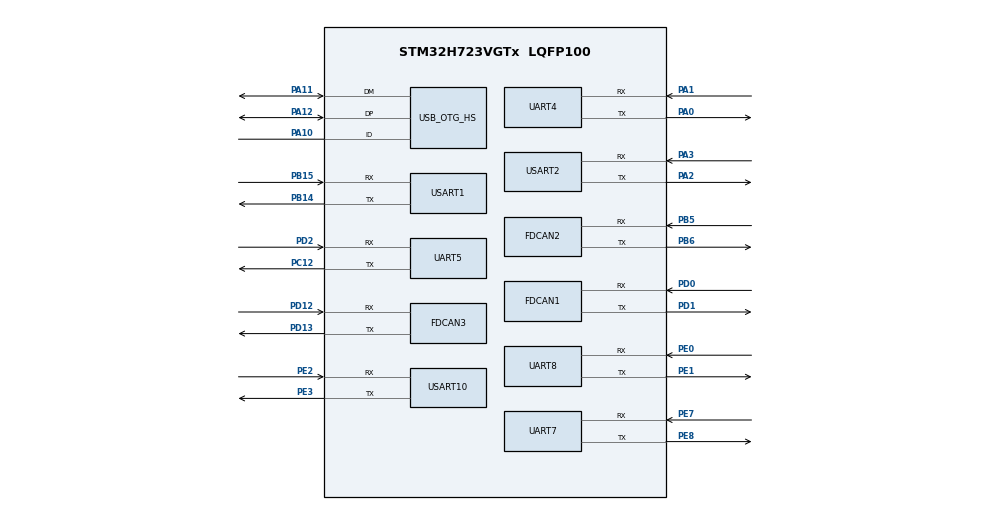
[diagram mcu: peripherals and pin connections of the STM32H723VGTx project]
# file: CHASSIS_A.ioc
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CORTEX_M7.default_mode_Activation=1
FDCAN1.AutoRetransmission=ENABLE
FDCAN1.CalculateBaudRateNominal=1000000
FDCAN1.CalculateTimeBitNominal=1000
FDCAN1.CalculateTimeQuantumNominal=62.5
FDCAN1.DataPrescaler=5
FDCAN1.DataSyncJumpWidth=2
FDCAN1.DataTimeSeg1=13
FDCAN1.DataTimeSeg2=2
FDCAN1.ExtFiltersNbr=1
FDCAN1.MessageRAMOffset=0
FDCAN1.NominalPrescaler=5
FDCAN1.NominalSyncJumpWidth=2
FDCAN1.NominalTimeSeg1=13
FDCAN1.NominalTimeSeg2=2
FDCAN1.RxFifo0ElmtsNbr=32
FDCAN1.StdFiltersNbr=1
FDCAN1.TxFifoQueueElmtsNbr=16
FDCAN2.AutoRetransmission=ENABLE
FDCAN2.CalculateBaudRateNominal=1000000
FDCAN2.CalculateTimeBitNominal=1000
FDCAN2.CalculateTimeQuantumNominal=62.5
FDCAN2.DataPrescaler=5
FDCAN2.DataSyncJumpWidth=2
FDCAN2.DataTimeSeg1=13
FDCAN2.DataTimeSeg2=2
FDCAN2.ExtFiltersNbr=1
FDCAN2.MessageRAMOffset=256
FDCAN2.NominalPrescaler=5
FDCAN2.NominalSyncJumpWidth=2
FDCAN2.NominalTimeSeg1=13
FDCAN2.NominalTimeSeg2=2
FDCAN2.RxFifo0ElmtsNbr=32
FDCAN2.StdFiltersNbr=1
FDCAN2.TxFifoQueueElmtsNbr=16
FDCAN3.AutoRetransmission=ENABLE
FDCAN3.CalculateBaudRateNominal=1000000
FDCAN3.CalculateTimeBitNominal=1000
FDCAN3.CalculateTimeQuantumNominal=62.5
FDCAN3.DataPrescaler=5
FDCAN3.DataSyncJumpWidth=2
FDCAN3.DataTimeSeg1=13
FDCAN3.DataTimeSeg2=2
FDCAN3.ExtFiltersNbr=1
FDCAN3.MessageRAMOffset=512
FDCAN3.NominalPrescaler=5
FDCAN3.NominalSyncJumpWidth=2
FDCAN3.NominalTimeSeg1=13
FDCAN3.NominalTimeSeg2=2
FDCAN3.RxFifo0ElmtsNbr=32
FDCAN3.StdFiltersNbr=1
FDCAN3.TxFifoQueueElmtsNbr=16
FREERTOS.Tasks01=defaultTask,32,512,StartDefaultTask,Default,NULL,Dynamic,NULL,NULL
FREERTOS.configCHECK_FOR_STACK_OVERFLOW=2
FREERTOS.configENABLE_FPU=1
FREERTOS.configMAX_TASK_NAME_LEN=24
FREERTOS.configQUEUE_REGISTRY_SIZE=16
FREERTOS.configTOTAL_HEAP_SIZE=65536
FREERTOS.configUSE_MALLOC_FAILED_HOOK=1
Mcu.Family=STM32H7
Mcu.Name=STM32H723VGTx
Mcu.Package=LQFP100
NVIC.FDCAN1_IT0_IRQn=true\:5\:0\:false\:false\:true\:true\:true\:true\:true
NVIC.FDCAN2_IT0_IRQn=true\:5\:0\:false\:false\:true\:true\:true\:true\:true
NVIC.FDCAN3_IT0_IRQn=true\:5\:0\:false\:false\:true\:true\:true\:true\:true
NVIC.PriorityGroup=NVIC_PRIORITYGROUP_4
NVIC.TIM1_UP_IRQn=true\:15\:0\:false\:false\:true\:false\:false\:true\:true
NVIC.TimeBase=TIM1_UP_IRQn
NVIC.TimeBaseIP=TIM1
PA0.Mode=Asynchronous
PA0.Signal=UART4_TX
PA1.Mode=Asynchronous
PA1.Signal=UART4_RX
PA10.Mode=OTG/Dual_Role_Device_FS
PA10.Signal=USB_OTG_HS_ID
PA11.Mode=OTG/Dual_Role_Device_FS
PA11.Signal=USB_OTG_HS_DM
PA12.Mode=OTG/Dual_Role_Device_FS
PA12.Signal=USB_OTG_HS_DP
PA13(JTMS/SWDIO).Mode=Serial_Wire
PA13(JTMS/SWDIO).Signal=DEBUG_JTMS-SWDIO
PA14(JTCK/SWCLK).Mode=Serial_Wire
PA14(JTCK/SWCLK).Signal=DEBUG_JTCK-SWCLK
PA2.Mode=Asynchronous
PA2.Signal=USART2_TX
PA3.Mode=Asynchronous
PA3.Signal=USART2_RX
PB14.Mode=Asynchronous
PB14.Signal=USART1_TX
PB15.Mode=Asynchronous
PB15.Signal=USART1_RX
PB5.Mode=FDCAN_Activate
PB5.Signal=FDCAN2_RX
PB6.Mode=FDCAN_Activate
PB6.Signal=FDCAN2_TX
PC12.GPIO_Speed=GPIO_SPEED_FREQ_HIGH
PC12.Mode=Asynchronous
PC12.Signal=UART5_TX
PD0.Mode=FDCAN_Activate
PD0.Signal=FDCAN1_RX
PD1.Mode=FDCAN_Activate
PD1.Signal=FDCAN1_TX
PD12.Mode=FDCAN_Activate
PD12.Signal=FDCAN3_RX
PD13.Mode=FDCAN_Activate
PD13.Signal=FDCAN3_TX
PD2.Mode=Asynchronous
PD2.Signal=UART5_RX
PE0.Mode=Asynchronous
PE0.Signal=UART8_RX
PE1.Mode=Asynchronous
PE1.Signal=UART8_TX
PE2.Mode=Asynchronous
PE2.Signal=USART10_RX
PE3.Mode=Asynchronous
PE3.Signal=USART10_TX
PE7.Mode=Asynchronous
PE7.Signal=UART7_RX
PE8.Mode=Asynchronous
PE8.Signal=UART7_TX
PH0-OSC_IN.Mode=HSE-External-Oscillator
PH0-OSC_IN.Signal=RCC_OSC_IN
PH1-OSC_OUT.Mode=HSE-External-Oscillator
PH1-OSC_OUT.Signal=RCC_OSC_OUT
ProjectManager.HeapSize=0x200
ProjectManager.StackSize=0x400
ProjectManager.TargetToolchain=MDK-ARM V5.32
RCC.ADCFreq_Value=200000000
RCC.APB1Freq_Value=137500000
RCC.APB2Freq_Value=137500000
RCC.APB3Freq_Value=137500000
RCC.APB4Freq_Value=137500000
RCC.CortexFreq_Value=550000000
RCC.D1PPRE=RCC_APB3_DIV2
RCC.D2PPRE1=RCC_APB1_DIV2
RCC.D2PPRE2=RCC_APB2_DIV2
RCC.D3PPRE=RCC_APB4_DIV2
RCC.DIVM1=2
RCC.DIVM2=5
RCC.DIVM3=5
RCC.DIVN1=44
RCC.DIVN2=80
RCC.DIVN3=40
RCC.DIVP1=1
RCC.DIVQ1=4
RCC.DIVQ2=5
RCC.FDCANCLockSelection=RCC_FDCANCLKSOURCE_PLL2
RCC.HCLKFreq_Value=275000000
RCC.HPRE=RCC_HCLK_DIV2
RCC.PLLFRACN=0
RCC.PLLSourceVirtual=RCC_PLLSOURCE_HSE
RCC.SYSCLKFreq_VALUE=550000000
RCC.SYSCLKSource=RCC_SYSCLKSOURCE_PLLCLK
RCC.USBCLockSelection=RCC_USBCLKSOURCE_PLL3
RCC.USBFreq_Value=100000000
USART1.VirtualMode-Asynchronous=VM_ASYNC
USART10.VirtualMode=VM_ASYNC
USART2.VirtualMode-Asynchronous=VM_ASYNC
USB_OTG_HS.VirtualMode-OTG/Dual_Role_Device_FS=Device_Role_Device_FS
VP_FREERTOS_VS_CMSIS_V2.Mode=CMSIS_V2
VP_MEMORYMAP_VS_MEMORYMAP.Mode=CurAppReg
VP_SYS_VS_tim1.Mode=TIM1
VP_TIM13_VS_ClockSourceINT.Mode=Enable_Timer
VP_TIM14_VS_ClockSourceINT.Mode=Enable_Timer
VP_TIM6_VS_ClockSourceINT.Mode=Enable_Timer
VP_TIM7_VS_ClockSourceINT.Mode=Enable_Timer
VP_USB_OTG_HS1_USB_OTG_HS_DR.Mode=activate
board=custom

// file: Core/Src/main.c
/* USER CODE BEGIN Header */
/**
  ******************************************************************************
  * @file           : main.c
  * @brief          : Main program body
  ******************************************************************************
  * @attention
  *
  * Copyright (c) 2026 STMicroelectronics.
  * All rights reserved.
  *
  * This software is licensed under terms that can be found in the LICENSE file
  * in the root directory of this software component.
  * If no LICENSE file comes with this software, it is provided AS-IS.
  *
  ******************************************************************************
  */
/* USER CODE END Header */
#include "main.h"
#include "FreeRTOS.h"
#include "cmsis_os2.h"
#include "fdcan.h"
#include "tim.h"
#include "usart.h"
#include "usb_otg.h"
#include "gpio.h"

/* USER CODE BEGIN Includes */
#include "Bsp_Control_Timer.h"

/* USER CODE END Includes */

void SystemClock_Config(void);
void PeriphCommonClock_Config(void);
static void MPU_Config(void);
void MX_FREERTOS_Init(void);

int main(void)
{

  /* MPU Configuration--------------------------------------------------------*/
  MPU_Config();

  /* MCU Configuration--------------------------------------------------------*/

  /* Reset of all peripherals, Initializes the Flash interface and the Systick. */
  HAL_Init();

  /* Configure the system clock */
  SystemClock_Config();

  /* Configure the peripherals common clocks */
  PeriphCommonClock_Config();

  /* Initialize all configured peripherals */
  MX_GPIO_Init();
  MX_FDCAN1_Init();
  MX_FDCAN2_Init();
  MX_FDCAN3_Init();
  MX_TIM6_Init();
  MX_TIM7_Init();
  MX_TIM13_Init();
  MX_TIM14_Init();
  MX_UART4_Init();
  MX_UART7_Init();
  MX_UART8_Init();
  MX_USART1_UART_Init();
  MX_USART10_UART_Init();
  MX_USB_OTG_HS_PCD_Init();
  MX_UART5_Init();
  MX_USART2_UART_Init();

  /* Init scheduler */
  osKernelInitialize();  /* Call init function for freertos objects (in cmsis_os2.c) */
  MX_FREERTOS_Init();

  /* Start scheduler */
  osKernelStart();

  /* We should never get here as control is now taken by the scheduler */

  /* Infinite loop */
  while (1)
  {

  }
}

void SystemClock_Config(void)
{
  RCC_OscInitTypeDef RCC_OscInitStruct = {0};
  RCC_ClkInitTypeDef RCC_ClkInitStruct = {0};

  /** Supply configuration update enable
  */
  HAL_PWREx_ConfigSupply(PWR_LDO_SUPPLY);

  /** Configure the main internal regulator output voltage
  */
  __HAL_PWR_VOLTAGESCALING_CONFIG(PWR_REGULATOR_VOLTAGE_SCALE0);

  while(!__HAL_PWR_GET_FLAG(PWR_FLAG_VOSRDY)) {}

  /** Initializes the RCC Oscillators according to the specified parameters
  * in the RCC_OscInitTypeDef structure.
  */
  RCC_OscInitStruct.OscillatorType = RCC_OSCILLATORTYPE_HSE;
  RCC_OscInitStruct.HSEState = RCC_HSE_ON;
  RCC_OscInitStruct.PLL.PLLState = RCC_PLL_ON;
  RCC_OscInitStruct.PLL.PLLSource = RCC_PLLSOURCE_HSE;
  RCC_OscInitStruct.PLL.PLLM = 2;
  RCC_OscInitStruct.PLL.PLLN = 44;
  RCC_OscInitStruct.PLL.PLLP = 1;
  RCC_OscInitStruct.PLL.PLLQ = 4;
  RCC_OscInitStruct.PLL.PLLR = 2;
  RCC_OscInitStruct.PLL.PLLRGE = RCC_PLL1VCIRANGE_3;
  RCC_OscInitStruct.PLL.PLLVCOSEL = RCC_PLL1VCOWIDE;
  RCC_OscInitStruct.PLL.PLLFRACN = 0;
  if (HAL_RCC_OscConfig(&RCC_OscInitStruct) != HAL_OK)
  {
    Error_Handler();
  }

  /** Initializes the CPU, AHB and APB buses clocks
  */
  RCC_ClkInitStruct.ClockType = RCC_CLOCKTYPE_HCLK|RCC_CLOCKTYPE_SYSCLK
                              |RCC_CLOCKTYPE_PCLK1|RCC_CLOCKTYPE_PCLK2
                              |RCC_CLOCKTYPE_D3PCLK1|RCC_CLOCKTYPE_D1PCLK1;
  RCC_ClkInitStruct.SYSCLKSource = RCC_SYSCLKSOURCE_PLLCLK;
  RCC_ClkInitStruct.SYSCLKDivider = RCC_SYSCLK_DIV1;
  RCC_ClkInitStruct.AHBCLKDivider = RCC_HCLK_DIV2;
  RCC_ClkInitStruct.APB3CLKDivider = RCC_APB3_DIV2;
  RCC_ClkInitStruct.APB1CLKDivider = RCC_APB1_DIV2;
  RCC_ClkInitStruct.APB2CLKDivider = RCC_APB2_DIV2;
  RCC_ClkInitStruct.APB4CLKDivider = RCC_APB4_DIV2;

  if (HAL_RCC_ClockConfig(&RCC_ClkInitStruct, FLASH_LATENCY_3) != HAL_OK)
  {
    Error_Handler();
  }
}

void PeriphCommonClock_Config(void)
{
  RCC_PeriphCLKInitTypeDef PeriphClkInitStruct = {0};

  /** Initializes the peripherals clock
  */
  PeriphClkInitStruct.PeriphClockSelection = RCC_PERIPHCLK_FDCAN;
  PeriphClkInitStruct.PLL2.PLL2M = 5;
  PeriphClkInitStruct.PLL2.PLL2N = 80;
  PeriphClkInitStruct.PLL2.PLL2P = 2;
  PeriphClkInitStruct.PLL2.PLL2Q = 5;
  PeriphClkInitStruct.PLL2.PLL2R = 2;
  PeriphClkInitStruct.PLL2.PLL2RGE = RCC_PLL2VCIRANGE_2;
  PeriphClkInitStruct.PLL2.PLL2VCOSEL = RCC_PLL2VCOWIDE;
  PeriphClkInitStruct.PLL2.PLL2FRACN = 0;
  PeriphClkInitStruct.FdcanClockSelection = RCC_FDCANCLKSOURCE_PLL2;
  if (HAL_RCCEx_PeriphCLKConfig(&PeriphClkInitStruct) != HAL_OK)
  {
    Error_Handler();
  }
}

 /* MPU Configuration */

void MPU_Config(void)
{
  MPU_Region_InitTypeDef MPU_InitStruct = {0};

  /* Disables the MPU */
  HAL_MPU_Disable();

  /** Initializes and configures the Region and the memory to be protected
  */
  MPU_InitStruct.Enable = MPU_REGION_ENABLE;
  MPU_InitStruct.Number = MPU_REGION_NUMBER0;
  MPU_InitStruct.BaseAddress = 0x0;
  MPU_InitStruct.Size = MPU_REGION_SIZE_4GB;
  MPU_InitStruct.SubRegionDisable = 0x87;
  MPU_InitStruct.TypeExtField = MPU_TEX_LEVEL0;
  MPU_InitStruct.AccessPermission = MPU_REGION_NO_ACCESS;
  MPU_InitStruct.DisableExec = MPU_INSTRUCTION_ACCESS_DISABLE;
  MPU_InitStruct.IsShareable = MPU_ACCESS_SHAREABLE;
  MPU_InitStruct.IsCacheable = MPU_ACCESS_NOT_CACHEABLE;
  MPU_InitStruct.IsBufferable = MPU_ACCESS_NOT_BUFFERABLE;

  HAL_MPU_ConfigRegion(&MPU_InitStruct);
  /* Enables the MPU */
  HAL_MPU_Enable(MPU_PRIVILEGED_DEFAULT);

}

void HAL_TIM_PeriodElapsedCallback(TIM_HandleTypeDef *htim)
{
  if (htim->Instance == TIM1)
  {
    HAL_IncTick();
  }
  /* USER CODE BEGIN Callback 1 */
  BspTim_DispatchPeriodElapsedFromISR(htim);

  /* USER CODE END Callback 1 */
}

void Error_Handler(void)
{
  __disable_irq();
  while (1)
  {
  }
}

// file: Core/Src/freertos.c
/* USER CODE BEGIN Header */
/**
  ******************************************************************************
  * File Name          : freertos.c
  * Description        : Code for freertos applications
  ******************************************************************************
  * @attention
  *
  * Copyright (c) 2026 STMicroelectronics.
  * All rights reserved.
  *
  * This software is licensed under terms that can be found in the LICENSE file
  * in the root directory of this software component.
  * If no LICENSE file comes with this software, it is provided AS-IS.
  *
  ******************************************************************************
  */
/* USER CODE END Header */

#include "FreeRTOS.h"
#include "task.h"
#include "main.h"
#include "FreeRTOS.h"
#include "cmsis_os2.h"

/* USER CODE BEGIN Includes */
#include "app_rtos.h"

/* USER CODE END Includes */

/* Definitions for defaultTask */
osThreadId_t defaultTaskHandle;
const osThreadAttr_t defaultTask_attributes = {
  .name = "defaultTask",
  .stack_size = 512 * 4,
  .priority = (osPriority_t) osPriorityAboveNormal,
};

void StartDefaultTask(void *argument);

void MX_FREERTOS_Init(void); /* (MISRA C 2004 rule 8.1) */

/* Hook prototypes */
void vApplicationStackOverflowHook(xTaskHandle xTask, char *pcTaskName);
void vApplicationMallocFailedHook(void);

/* USER CODE BEGIN 4 */
void vApplicationStackOverflowHook(xTaskHandle xTask, char *pcTaskName)
{
  (void)xTask;
  appRtosFaultFile = pcTaskName;
  AppRtos_Panic(APP_RTOS_FAULT_STACK_OVERFLOW);
}
/* USER CODE END 4 */

/* USER CODE BEGIN 5 */
void vApplicationMallocFailedHook(void)
{
  AppRtos_Panic(APP_RTOS_FAULT_MALLOC_FAILED);
}
/* USER CODE END 5 */

void MX_FREERTOS_Init(void) {
  /* USER CODE BEGIN Init */
  if (!AppRtos_Init())
  {
    AppRtos_Panic(APP_RTOS_FAULT_OBJECT_CREATE);
  }

  /* USER CODE END Init */

  /* Create the thread(s) */
  /* creation of defaultTask */
  defaultTaskHandle = osThreadNew(StartDefaultTask, NULL, &defaultTask_attributes);

}

void StartDefaultTask(void *argument)
{
  /* USER CODE BEGIN StartDefaultTask */
  (void)argument;
  AppRtos_Bootstrap();
  osThreadExit();
  /* USER CODE END StartDefaultTask */
}

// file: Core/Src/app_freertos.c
#include "app_freertos.h"

#include <string.h>

#include "FreeRTOS.h"
#include "fdcan.h"
#include "task.h"

#define APP_CAN_RX_QUEUE_LENGTH           64U
#define APP_COMMAND_QUEUE_LENGTH           4U
#define APP_COMM_QUEUE_LENGTH             16U
#define APP_TELEMETRY_QUEUE_LENGTH         4U

#define APP_CONTROL_PERIOD_MS              1U
#define APP_NAVIGATION_PERIOD_MS          10U
#define APP_SAFETY_PERIOD_MS              10U
#define APP_MONITOR_PERIOD_MS            100U

#define APP_CAN_RX_TASK_STACK_SIZE       1536U
#define APP_CONTROL_TASK_STACK_SIZE      2048U
#define APP_NAVIGATION_TASK_STACK_SIZE   3072U
#define APP_COMM_TASK_STACK_SIZE         2048U
#define APP_SAFETY_TASK_STACK_SIZE       1024U
#define APP_MONITOR_TASK_STACK_SIZE      1024U

osThreadId_t appCanRxTaskHandle;
osThreadId_t appControlTaskHandle;
osThreadId_t appNavigationTaskHandle;
osThreadId_t appCommunicationTaskHandle;
osThreadId_t appSafetyTaskHandle;
osThreadId_t appMonitorTaskHandle;

osMessageQueueId_t appCanRxQueueHandle;
osMessageQueueId_t appChassisCommandQueueHandle;
osMessageQueueId_t appMechanismCommandQueueHandle;
osMessageQueueId_t appTrajectoryQueueHandle;
osMessageQueueId_t appCommunicationQueueHandle;
osMessageQueueId_t appTelemetryQueueHandle;
osEventFlagsId_t appSystemEventHandle;
osMutexId_t appRobotStateMutexHandle;

volatile app_freertos_fault_t appFreertosFaultCode = APP_FREERTOS_FAULT_NONE;
volatile uint32_t appFreertosFaultLine;
const char * volatile appFreertosFaultFile;

static app_robot_state_t app_robot_state;
static app_runtime_stats_t app_runtime_stats;
static volatile uint32_t app_can_error_mask;

static void AppCanRxTask(void *argument);
static void AppControlTask(void *argument);
static void AppNavigationTask(void *argument);
static void AppCommunicationTask(void *argument);
static void AppSafetyTask(void *argument);
static void AppMonitorTask(void *argument);

static const osThreadAttr_t app_can_rx_task_attributes =
{
    .name = "canRxTask",
    .stack_size = APP_CAN_RX_TASK_STACK_SIZE,
    .priority = osPriorityHigh
};

static const osThreadAttr_t app_control_task_attributes =
{
    .name = "controlTask",
    .stack_size = APP_CONTROL_TASK_STACK_SIZE,
    .priority = osPriorityRealtime
};

static const osThreadAttr_t app_navigation_task_attributes =
{
    .name = "navigationTask",
    .stack_size = APP_NAVIGATION_TASK_STACK_SIZE,
    .priority = osPriorityAboveNormal
};

static const osThreadAttr_t app_communication_task_attributes =
{
    .name = "communicationTask",
    .stack_size = APP_COMM_TASK_STACK_SIZE,
    .priority = osPriorityNormal
};

static const osThreadAttr_t app_safety_task_attributes =
{
    .name = "safetyTask",
    .stack_size = APP_SAFETY_TASK_STACK_SIZE,
    .priority = osPriorityHigh
};

static const osThreadAttr_t app_monitor_task_attributes =
{
    .name = "monitorTask",
    .stack_size = APP_MONITOR_TASK_STACK_SIZE,
    .priority = osPriorityLow
};

static const osMessageQueueAttr_t app_can_rx_queue_attributes =
{
    .name = "canRxQueue"
};

static const osMessageQueueAttr_t app_chassis_command_queue_attributes =
{
    .name = "chassisCmdQueue"
};

static const osMessageQueueAttr_t app_mechanism_command_queue_attributes =
{
    .name = "mechanismCmdQueue"
};

static const osMessageQueueAttr_t app_trajectory_queue_attributes =
{
    .name = "trajectoryQueue"
};

static const osMessageQueueAttr_t app_communication_queue_attributes =
{
    .name = "communicationQueue"
};

static const osMessageQueueAttr_t app_telemetry_queue_attributes =
{
    .name = "telemetryQueue"
};

static const osEventFlagsAttr_t app_system_event_attributes =
{
    .name = "systemEvents"
};

static const osMutexAttr_t app_state_mutex_attributes =
{
    .name = "robotStateMutex",
    .attr_bits = osMutexPrioInherit
};

static uint32_t App_MsToTicks(uint32_t milliseconds)
{
    uint64_t ticks;

    ticks = ((uint64_t)milliseconds * osKernelGetTickFreq() + 999U) / 1000U;
    if ((milliseconds > 0U) && (ticks == 0U))
    {
        ticks = 1U;
    }
    return (uint32_t)ticks;
}

static bool App_WaitForInitialization(void)
{
    uint32_t flags;

    flags = osEventFlagsWait(appSystemEventHandle,
                             APP_EVENT_INIT_DONE | APP_EVENT_INIT_FAILED,
                             osFlagsWaitAny | osFlagsNoClear, osWaitForever);
    return ((flags & osFlagsError) == 0U)
        && ((flags & APP_EVENT_INIT_DONE) != 0U);
}

static bool App_StartCan(FDCAN_HandleTypeDef *handle, uint32_t ready_event)
{
    FDCAN_FilterTypeDef filter = {0};

    filter.IdType = FDCAN_STANDARD_ID;
    filter.FilterIndex = 0U;
    filter.FilterType = FDCAN_FILTER_MASK;
    filter.FilterConfig = FDCAN_FILTER_TO_RXFIFO0;
    filter.FilterID1 = 0U;
    filter.FilterID2 = 0U;
    if (HAL_FDCAN_ConfigFilter(handle, &filter) != HAL_OK)
    {
        return false;
    }

    filter.IdType = FDCAN_EXTENDED_ID;
    if (HAL_FDCAN_ConfigFilter(handle, &filter) != HAL_OK)
    {
        return false;
    }

    if (HAL_FDCAN_ConfigGlobalFilter(handle, FDCAN_REJECT,
                                     FDCAN_REJECT, FDCAN_REJECT_REMOTE,
                                     FDCAN_REJECT_REMOTE) != HAL_OK)
    {
        return false;
    }

    if (HAL_FDCAN_Start(handle) != HAL_OK)
    {
        return false;
    }

    if (HAL_FDCAN_ActivateNotification(
            handle, FDCAN_IT_RX_FIFO0_NEW_MESSAGE | FDCAN_IT_BUS_OFF,
            0U) != HAL_OK)
    {
        (void)HAL_FDCAN_Stop(handle);
        return false;
    }

    (void)osEventFlagsSet(appSystemEventHandle, ready_event);
    return true;
}

static uint8_t App_FdcanDataLengthToBytes(uint32_t data_length)
{
    switch (data_length)
    {
    case FDCAN_DLC_BYTES_0:
        return 0U;
    case FDCAN_DLC_BYTES_1:
        return 1U;
    case FDCAN_DLC_BYTES_2:
        return 2U;
    case FDCAN_DLC_BYTES_3:
        return 3U;
    case FDCAN_DLC_BYTES_4:
        return 4U;
    case FDCAN_DLC_BYTES_5:
        return 5U;
    case FDCAN_DLC_BYTES_6:
        return 6U;
    case FDCAN_DLC_BYTES_7:
        return 7U;
    case FDCAN_DLC_BYTES_8:
        return 8U;
    default:
        return 0U;
    }
}

static bool App_GetCanBus(const FDCAN_HandleTypeDef *handle,
                          app_can_bus_t *bus)
{
    if (handle == &hfdcan1)
    {
        *bus = APP_CAN_BUS_1;
    }
    else if (handle == &hfdcan2)
    {
        *bus = APP_CAN_BUS_2;
    }
    else if (handle == &hfdcan3)
    {
        *bus = APP_CAN_BUS_3;
    }
    else
    {
        return false;
    }
    return true;
}

static bool App_PutLatestChassisCommand(
    const app_chassis_command_t *command, uint32_t timeout_ticks)
{
    app_chassis_command_t discarded;

    if (osMessageQueuePut(appChassisCommandQueueHandle, command, 0U,
                          timeout_ticks) == osOK)
    {
        return true;
    }
    if (osMessageQueueGet(appChassisCommandQueueHandle, &discarded, NULL,
                          0U) != osOK)
    {
        return false;
    }
    return osMessageQueuePut(appChassisCommandQueueHandle, command, 0U,
                             0U) == osOK;
}

static bool App_PutLatestMechanismCommand(
    const app_mechanism_command_t *command, uint32_t timeout_ticks)
{
    app_mechanism_command_t discarded;

    if (osMessageQueuePut(appMechanismCommandQueueHandle, command, 0U,
                          timeout_ticks) == osOK)
    {
        return true;
    }
    if (osMessageQueueGet(appMechanismCommandQueueHandle, &discarded, NULL,
                          0U) != osOK)
    {
        return false;
    }
    return osMessageQueuePut(appMechanismCommandQueueHandle, command, 0U,
                             0U) == osOK;
}

bool AppFreertos_Init(void)
{
    memset(&app_robot_state, 0, sizeof(app_robot_state));
    memset(&app_runtime_stats, 0, sizeof(app_runtime_stats));
    app_can_error_mask = 0U;

    appCanRxQueueHandle = osMessageQueueNew(APP_CAN_RX_QUEUE_LENGTH,
        sizeof(app_can_frame_t), &app_can_rx_queue_attributes);
    appChassisCommandQueueHandle = osMessageQueueNew(
        APP_COMMAND_QUEUE_LENGTH, sizeof(app_chassis_command_t),
        &app_chassis_command_queue_attributes);
    appMechanismCommandQueueHandle = osMessageQueueNew(
        APP_COMMAND_QUEUE_LENGTH, sizeof(app_mechanism_command_t),
        &app_mechanism_command_queue_attributes);
    appTrajectoryQueueHandle = osMessageQueueNew(
        APP_TRAJECTORY_QUEUE_LENGTH, sizeof(app_trajectory_point_t),
        &app_trajectory_queue_attributes);
    appCommunicationQueueHandle = osMessageQueueNew(
        APP_COMM_QUEUE_LENGTH, sizeof(app_comm_packet_t),
        &app_communication_queue_attributes);
    appTelemetryQueueHandle = osMessageQueueNew(
        APP_TELEMETRY_QUEUE_LENGTH, sizeof(app_runtime_stats_t),
        &app_telemetry_queue_attributes);
    appSystemEventHandle = osEventFlagsNew(&app_system_event_attributes);
    appRobotStateMutexHandle = osMutexNew(&app_state_mutex_attributes);

    if ((appCanRxQueueHandle == NULL)
        || (appChassisCommandQueueHandle == NULL)
        || (appMechanismCommandQueueHandle == NULL)
        || (appTrajectoryQueueHandle == NULL)
        || (appCommunicationQueueHandle == NULL)
        || (appTelemetryQueueHandle == NULL)
        || (appSystemEventHandle == NULL)
        || (appRobotStateMutexHandle == NULL))
    {
        return false;
    }

    appCanRxTaskHandle = osThreadNew(AppCanRxTask, NULL,
                                     &app_can_rx_task_attributes);
    appControlTaskHandle = osThreadNew(AppControlTask, NULL,
                                       &app_control_task_attributes);
    appNavigationTaskHandle = osThreadNew(AppNavigationTask, NULL,
                                          &app_navigation_task_attributes);
    appCommunicationTaskHandle = osThreadNew(
        AppCommunicationTask, NULL, &app_communication_task_attributes);
    appSafetyTaskHandle = osThreadNew(AppSafetyTask, NULL,
                                      &app_safety_task_attributes);
    appMonitorTaskHandle = osThreadNew(AppMonitorTask, NULL,
                                       &app_monitor_task_attributes);

    return (appCanRxTaskHandle != NULL)
        && (appControlTaskHandle != NULL)
        && (appNavigationTaskHandle != NULL)
        && (appCommunicationTaskHandle != NULL)
        && (appSafetyTaskHandle != NULL)
        && (appMonitorTaskHandle != NULL);
}

void AppFreertos_Bootstrap(void)
{
    bool initialized;

    initialized = App_StartCan(&hfdcan1, APP_EVENT_CAN1_READY);
    initialized = App_StartCan(&hfdcan2, APP_EVENT_CAN2_READY) && initialized;
    initialized = App_StartCan(&hfdcan3, APP_EVENT_CAN3_READY) && initialized;

    if (initialized)
    {
        (void)osEventFlagsSet(appSystemEventHandle, APP_EVENT_INIT_DONE);
    }
    else
    {
        (void)osEventFlagsSet(appSystemEventHandle,
                              APP_EVENT_INIT_FAILED | APP_EVENT_ESTOP);
    }
}

bool AppFreertos_SubmitChassisCommand(const app_chassis_command_t *command,
                                      uint32_t timeout_ms)
{
    if ((command == NULL) || (appChassisCommandQueueHandle == NULL))
    {
        return false;
    }
    return App_PutLatestChassisCommand(command, App_MsToTicks(timeout_ms));
}

bool AppFreertos_SubmitMechanismCommand(
    const app_mechanism_command_t *command, uint32_t timeout_ms)
{
    if ((command == NULL) || (appMechanismCommandQueueHandle == NULL))
    {
        return false;
    }
    return App_PutLatestMechanismCommand(command, App_MsToTicks(timeout_ms));
}

bool AppFreertos_SubmitTrajectoryPoint(const app_trajectory_point_t *point,
                                       uint32_t timeout_ms)
{
    if ((point == NULL) || (appTrajectoryQueueHandle == NULL))
    {
        return false;
    }
    return osMessageQueuePut(appTrajectoryQueueHandle, point, 0U,
                             App_MsToTicks(timeout_ms)) == osOK;
}

bool AppFreertos_SubmitCommunicationPacket(const app_comm_packet_t *packet,
                                            uint32_t timeout_ms)
{
    if ((packet == NULL) || (packet->length > APP_COMM_PAYLOAD_MAX_SIZE)
        || (appCommunicationQueueHandle == NULL))
    {
        return false;
    }

    if (osMessageQueuePut(appCommunicationQueueHandle, packet, 0U,
                          App_MsToTicks(timeout_ms)) != osOK)
    {
        app_runtime_stats.comm_rx_dropped++;
        return false;
    }
    return true;
}

bool AppFreertos_PublishRobotState(const app_robot_state_t *state,
                                   uint32_t timeout_ms)
{
    if ((state == NULL) || (appRobotStateMutexHandle == NULL)
        || (osMutexAcquire(appRobotStateMutexHandle,
                           App_MsToTicks(timeout_ms)) != osOK))
    {
        return false;
    }
    app_robot_state = *state;
    (void)osMutexRelease(appRobotStateMutexHandle);
    return true;
}

bool AppFreertos_GetRobotState(app_robot_state_t *state,
                               uint32_t timeout_ms)
{
    if ((state == NULL) || (appRobotStateMutexHandle == NULL)
        || (osMutexAcquire(appRobotStateMutexHandle,
                           App_MsToTicks(timeout_ms)) != osOK))
    {
        return false;
    }
    *state = app_robot_state;
    (void)osMutexRelease(appRobotStateMutexHandle);
    return true;
}

void AppFreertos_GetRuntimeStats(app_runtime_stats_t *stats)
{
    if (stats != NULL)
    {
        *stats = app_runtime_stats;
        stats->timestamp_ms = osKernelGetTickCount();
        stats->system_events = (appSystemEventHandle != NULL)
            ? osEventFlagsGet(appSystemEventHandle) : 0U;
        stats->can_error_mask = app_can_error_mask;
    }
}

void AppFreertos_NotifyCanErrorFromISR(app_can_bus_t bus)
{
    if (bus <= APP_CAN_BUS_3)
    {
        app_can_error_mask |= (1UL << (uint32_t)bus);
    }
}

static void AppCanRxTask(void *argument)
{
    app_can_frame_t frame;
    uint32_t ready_event;

    (void)argument;
    if (!App_WaitForInitialization())
    {
        osThreadExit();
    }

    for (;;)
    {
        if (osMessageQueueGet(appCanRxQueueHandle, &frame, NULL,
                              osWaitForever) == osOK)
        {
            app_runtime_stats.can_rx_count++;
            ready_event = APP_EVENT_CAN1_READY << (uint32_t)frame.bus;
            (void)osEventFlagsSet(appSystemEventHandle, ready_event);
            App_OnCanFrame(&frame);
        }
    }
}

static void AppControlTask(void *argument)
{
    app_chassis_command_t chassis_command = {0};
    app_mechanism_command_t mechanism_command = {0};
    uint32_t period_ticks;
    uint32_t next_wake;
    uint32_t system_events;

    (void)argument;
    if (!App_WaitForInitialization())
    {
        osThreadExit();
    }

    next_wake = osKernelGetTickCount();
    period_ticks = App_MsToTicks(APP_CONTROL_PERIOD_MS);
    for (;;)
    {
        while (osMessageQueueGet(appChassisCommandQueueHandle,
                                 &chassis_command, NULL, 0U) == osOK)
        {
        }
        while (osMessageQueueGet(appMechanismCommandQueueHandle,
                                 &mechanism_command, NULL, 0U) == osOK)
        {
        }

        system_events = osEventFlagsGet(appSystemEventHandle);
        if ((system_events & (APP_EVENT_ESTOP | APP_EVENT_MOTOR_FAULT
                              | APP_EVENT_CAN_FAULT)) != 0U)
        {
            chassis_command.valid = 0U;
            mechanism_command.valid = 0U;
        }

        App_ControlStep(&chassis_command, &mechanism_command, system_events);
        app_runtime_stats.control_cycle_count++;

        next_wake += period_ticks;
        if ((int32_t)(osKernelGetTickCount() - next_wake) >= 0)
        {
            app_runtime_stats.control_overrun_count++;
        }
        (void)osDelayUntil(next_wake);
    }
}

static void AppNavigationTask(void *argument)
{
    app_trajectory_point_t point = {0};
    bool point_available;
    uint32_t next_wake;

    (void)argument;
    if (!App_WaitForInitialization())
    {
        osThreadExit();
    }

    next_wake = osKernelGetTickCount();
    for (;;)
    {
        point_available = osMessageQueueGet(appTrajectoryQueueHandle, &point,
                                            NULL, 0U) == osOK;
        App_NavigationStep(&point, point_available);
        next_wake += App_MsToTicks(APP_NAVIGATION_PERIOD_MS);
        (void)osDelayUntil(next_wake);
    }
}

static void AppCommunicationTask(void *argument)
{
    app_comm_packet_t packet;

    (void)argument;
    if (!App_WaitForInitialization())
    {
        osThreadExit();
    }

    for (;;)
    {
        if (osMessageQueueGet(appCommunicationQueueHandle, &packet, NULL,
                              osWaitForever) == osOK)
        {
            app_runtime_stats.comm_rx_count++;
            App_OnCommunicationPacket(&packet);
        }
    }
}

static void AppSafetyTask(void *argument)
{
    uint32_t next_wake;
    uint32_t system_events;

    (void)argument;
    next_wake = osKernelGetTickCount();
    for (;;)
    {
        if (app_can_error_mask != 0U)
        {
            (void)osEventFlagsSet(appSystemEventHandle,
                                  APP_EVENT_CAN_FAULT | APP_EVENT_ESTOP);
        }
        system_events = osEventFlagsGet(appSystemEventHandle);
        App_SafetyStep(system_events);

        next_wake += App_MsToTicks(APP_SAFETY_PERIOD_MS);
        (void)osDelayUntil(next_wake);
    }
}

static void AppMonitorTask(void *argument)
{
    app_runtime_stats_t stats;
    app_runtime_stats_t discarded;
    uint32_t next_wake;

    (void)argument;
    next_wake = osKernelGetTickCount();
    for (;;)
    {
        AppFreertos_GetRuntimeStats(&stats);
        if (osMessageQueuePut(appTelemetryQueueHandle, &stats, 0U, 0U)
            != osOK)
        {
            (void)osMessageQueueGet(appTelemetryQueueHandle, &discarded,
                                    NULL, 0U);
            (void)osMessageQueuePut(appTelemetryQueueHandle, &stats, 0U, 0U);
        }
        App_MonitorStep(&stats);

        next_wake += App_MsToTicks(APP_MONITOR_PERIOD_MS);
        (void)osDelayUntil(next_wake);
    }
}

void HAL_FDCAN_RxFifo0Callback(FDCAN_HandleTypeDef *handle,
                               uint32_t rx_fifo0_its)
{
    FDCAN_RxHeaderTypeDef header;
    app_can_frame_t frame;

    (void)rx_fifo0_its;
    if ((appCanRxQueueHandle == NULL) || !App_GetCanBus(handle, &frame.bus))
    {
        return;
    }

    while (HAL_FDCAN_GetRxFifoFillLevel(handle, FDCAN_RX_FIFO0) > 0U)
    {
        if (HAL_FDCAN_GetRxMessage(handle, FDCAN_RX_FIFO0, &header,
                                   frame.data) != HAL_OK)
        {
            AppFreertos_NotifyCanErrorFromISR(frame.bus);
            break;
        }

        frame.timestamp_ms = HAL_GetTick();
        frame.identifier = header.Identifier;
        frame.is_extended_id =
            (header.IdType == FDCAN_EXTENDED_ID) ? 1U : 0U;
        frame.length = App_FdcanDataLengthToBytes(header.DataLength);
        if (osMessageQueuePut(appCanRxQueueHandle, &frame, 0U, 0U) != osOK)
        {
            app_runtime_stats.can_rx_dropped++;
        }
    }
}

void HAL_FDCAN_ErrorStatusCallback(FDCAN_HandleTypeDef *handle,
                                   uint32_t error_status_its)
{
    app_can_bus_t bus;

    (void)error_status_its;
    if (App_GetCanBus(handle, &bus))
    {
        AppFreertos_NotifyCanErrorFromISR(bus);
    }
}

void App_FreertosAssert(const char *file, uint32_t line)
{
    appFreertosFaultFile = file;
    appFreertosFaultLine = line;
    AppFreertos_Panic(APP_FREERTOS_FAULT_ASSERT);
}

void AppFreertos_Panic(app_freertos_fault_t fault)
{
    appFreertosFaultCode = fault;
    __disable_irq();
    for (;;)
    {
        __NOP();
    }
}

__weak void App_OnCanFrame(const app_can_frame_t *frame)
{
    (void)frame;
}

__weak void App_ControlStep(const app_chassis_command_t *chassis_command,
                            const app_mechanism_command_t *mechanism_command,
                            uint32_t system_events)
{
    (void)chassis_command;
    (void)mechanism_command;
    (void)system_events;
}

__weak void App_NavigationStep(const app_trajectory_point_t *point,
                               bool point_available)
{
    (void)point;
    (void)point_available;
}

__weak void App_OnCommunicationPacket(const app_comm_packet_t *packet)
{
    (void)packet;
}

__weak void App_SafetyStep(uint32_t system_events)
{
    (void)system_events;
}

__weak void App_MonitorStep(const app_runtime_stats_t *stats)
{
    (void)stats;
}
